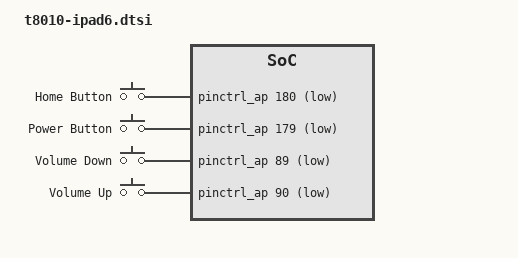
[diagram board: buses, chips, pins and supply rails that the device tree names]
// SPDX-License-Identifier: GPL-2.0+ OR MIT
/*
 * Apple iPad 6 common device tree
 *
 * Copyright (c) 2022, Konrad Dybcio <konradybcio@kernel.org>
 */

#include "t8010.dtsi"
#include "t8010-common.dtsi"
#include <dt-bindings/input/input.h>

/ {
	chassis-type = "tablet";

	gpio-keys {
		compatible = "gpio-keys";

		button-home {
			label = "Home Button";
			gpios = <&pinctrl_ap 180 GPIO_ACTIVE_LOW>;
			linux,code = <KEY_HOMEPAGE>;
			wakeup-source;
		};

		button-power {
			label = "Power Button";
			gpios = <&pinctrl_ap 179 GPIO_ACTIVE_LOW>;
			linux,code = <KEY_POWER>;
			wakeup-source;
		};

		button-voldown {
			label = "Volume Down";
			gpios = <&pinctrl_ap 89 GPIO_ACTIVE_LOW>;
			linux,code = <KEY_VOLUMEDOWN>;
		};

		button-volup {
			label = "Volume Up";
			gpios = <&pinctrl_ap 90 GPIO_ACTIVE_LOW>;
			linux,code = <KEY_VOLUMEUP>;
		};
	};
};
